# ESPCTL_1 register map
Vendor: Texas Instruments
Peripheral module from a debugger description file (folder msp430).
Registers are 16-bit, access not given, no defined reset value unless marked. A register's access mark holds for its fields unless they carry their own. Offsets are as the file gives them; lines under a group give offsets from that group; [hi:lo] are bit positions; {n}, {i} and the like mark numbered series; 'fields as' and 'values as' point back to an identical list; <NAME> marks a mode.

## ESPCTL
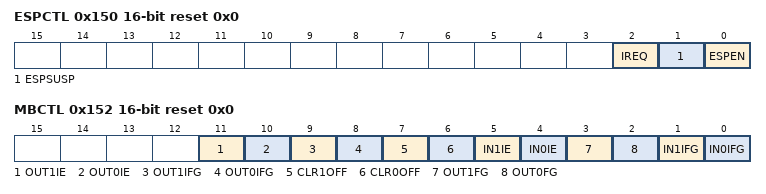
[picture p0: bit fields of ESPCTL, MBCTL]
0x150 ESPCTL rw reset 0x0 — ESP430 Control Register
  [2] IREQ — NOT supported by current ESP430 Software
  [1] ESPSUSP — ESP430 Module suspend
  [0] ESPEN — ESP430 Module enable
0x152 MBCTL rw reset 0x0 — Mailbox Control Register
  [11] OUT1IE — Outgoing Mail 1 Interrupt Enable
  [10] OUT0IE — Outgoing Mail 0 Interrupt Enable
  [9] OUT1IFG — Outgoing Mail 1 Interrupt Flag
  [8] OUT0IFG — Outgoing Mail 0 Interrupt Flag
  [7] CLR1OFF — Switch off automatic clear of IN1IFG
  [6] CLR0OFF — Switch off automatic clear of IN0IFG
  [5] IN1IE — Incoming Mail 1 Interrupt Enable
  [4] IN0IE — Incoming Mail 0 Interrupt Enable
  [3] OUT1FG — Outgoing Mail 1 Flag
  [2] OUT0FG — Outgoing Mail 0 Flag
  [1] IN1IFG — Incoming Mail 1 Interrupt Flag
  [0] IN0IFG — Incoming Mail 0 Interrupt Flag
0x154 MBIN0 — Incoming Mailbox 0 Register
0x156 MBIN1 — Incoming Mailbox 1 Register
0x158 MBOUT0 — Outgoing Mailbox 0 Register
0x15A MBOUT1 — Outgoing Mailbox 1 Register
0x1C0 ESP430_STAT0 — ESP430 Return Value 0
0x1C2 ESP430_STAT1 — ESP430 Return Value 1
0x1C4 WAVEFSV1 — ESP430 Return Value 2
0x1C6 RET3 — ESP430 Return Value 3
0x1C8 RET4 — ESP430 Return Value 4
0x1CA WAVEFSI1 — ESP430 Return Value 5
0x1CC WAVEFSI2 — ESP430 Return Value 6
0x1CE RET7 — ESP430 Return Value 7
0x1D0 ACTENERGY1_LO — ESP430 Return Value 8
0x1D2 ACTENERGY1_HI — ESP430 Return Value 9
0x1D4 ACTENERGY2_LO — ESP430 Return Value 10
0x1D6 ACTENERGY2_HI — ESP430 Return Value 11
0x1D8 REACTENERGY_LO — ESP430 Return Value 12
0x1DA REACTENERGY_HI — ESP430 Return Value 13
0x1DC APPENERGY_LO — ESP430 Return Value 14
0x1DE APPENERGY_HI — ESP430 Return Value 15
0x1E0 ACTENSPER1_LO — ESP430 Return Value 16
0x1E2 ACTENSPER1_HI — ESP430 Return Value 17
0x1E4 ACTENSPER2_LO — ESP430 Return Value 18
0x1E6 ACTENSPER2_HI — ESP430 Return Value 19
0x1E8 POWERFCT — ESP430 Return Value 20
0x1EA CAPIND — ESP430 Return Value 21
0x1EC MAINSPERIOD — ESP430 Return Value 22
0x1EE V1RMS — ESP430 Return Value 23
0x1F0 IRMS_LO — ESP430 Return Value 24
0x1F2 IRMS_HI — ESP430 Return Value 25
0x1F4 VPEAK — ESP430 Return Value 26
0x1F6 IPEAK — ESP430 Return Value 27
0x1F8 LINECYCLCNT_LO — ESP430 Return Value 28
0x1FA LINECYCLCNT_HI — ESP430 Return Value 29
0x1FC NMBMEAS_LO — ESP430 Return Value 30
0x1FE NMBMEAS_HI — ESP430 Return Value 31
